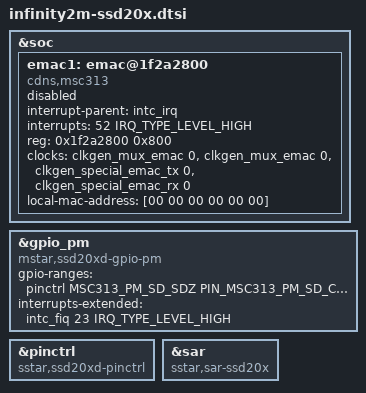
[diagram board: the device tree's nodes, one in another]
// SPDX-License-Identifier: GPL-2.0
/*
 * Copyright (c) 2020 thingy.jp.
 * Author: Daniel Palmer <daniel@thingy.jp>
 */

#include <dt-bindings/gpio/mstar.h>
#include <dt-bindings/pinctrl/mstar.h>

#include "infinity2m.dtsi"

&soc {
	emac1: emac@1f2a2800 {
		#address-cells = <1>;
		#size-cells = <0>;
		compatible = "cdns,msc313";
		interrupt-parent = <&intc_irq>;
		interrupts = <52 IRQ_TYPE_LEVEL_HIGH>;
		reg = <0x1f2a2800 0x800>;
		clock-names = "pclk", "hclk", "tx_clk", "rx_clk";
		clocks = <&clkgen_mux_emac 0>,
			 <&clkgen_mux_emac 0>,
			 <&clkgen_special_emac_tx 0>,
			 <&clkgen_special_emac_rx 0>;
		local-mac-address = [00 00 00 00 00 00];
		status = "disabled";
	};
};

&gpio_pm {
	compatible = "mstar,ssd20xd-gpio-pm";
	gpio-ranges = <&pinctrl MSC313_PM_SD_SDZ PIN_MSC313_PM_SD_CDZ 1>;
	interrupts-extended = <&intc_fiq 23 IRQ_TYPE_LEVEL_HIGH>;
	status = "okay";
};

&pinctrl {
	compatible = "sstar,ssd20xd-pinctrl";
};

&sar {
	compatible = "sstar,sar-ssd20x";
};
